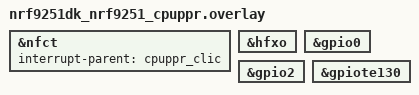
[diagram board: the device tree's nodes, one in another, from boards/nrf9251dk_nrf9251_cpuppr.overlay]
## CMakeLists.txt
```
#
# Copyright (c) 2018 Nordic Semiconductor
#
# SPDX-License-Identifier: LicenseRef-Nordic-5-Clause
#

cmake_minimum_required(VERSION 3.20.0)

find_package(Zephyr REQUIRED HINTS $ENV{ZEPHYR_BASE})
project(NONE)

FILE(GLOB app_sources src/*.c)
# NORDIC SDK APP START
target_sources(app  PRIVATE ${app_sources})
# NORDIC SDK APP END
```

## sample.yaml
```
sample:
  name: NFC text record sample
tests:
  sample.nfc.record_text:
    sysbuild: true
    build_only: true
    integration_platforms:
      - nrf52840dk/nrf52840
      - nrf5340dk/nrf5340/cpuapp
      - nrf5340dk/nrf5340/cpuapp/ns
      - nrf54h20dk/nrf54h20/cpuapp
      - nrf54l15dk/nrf54l05/cpuapp
      - nrf54l15dk/nrf54l10/cpuapp
      - nrf54l15dk/nrf54l15/cpuapp
      - nrf54l15dk/nrf54l15/cpuapp/ns
      - nrf54lm20dk/nrf54lm20a/cpuapp
      - nrf7120dk/nrf7120/cpuapp
    platform_allow:
      - nrf52840dk/nrf52840
      - nrf52dk/nrf52832
      - nrf5340dk/nrf5340/cpuapp
      - nrf5340dk/nrf5340/cpuapp/ns
      - nrf54h20dk/nrf54h20/cpuapp
      - nrf54l15dk/nrf54l05/cpuapp
      - nrf54l15dk/nrf54l10/cpuapp
      - nrf54l15dk/nrf54l15/cpuapp
      - nrf54l15dk/nrf54l15/cpuapp/ns
      - nrf54lm20dk/nrf54lm20a/cpuapp
      - nrf7120dk/nrf7120/cpuapp
    tags:
      - ci_build
      - sysbuild
      - ci_samples_nfc
```

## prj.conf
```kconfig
#
# Copyright (c) 2019 Nordic Semiconductor ASA
#
# SPDX-License-Identifier: LicenseRef-Nordic-5-Clause
#
CONFIG_NCS_SAMPLES_DEFAULTS=y

CONFIG_REBOOT=y
CONFIG_DK_LIBRARY=y

CONFIG_NFC_T2T_NRFXLIB=y

CONFIG_NFC_NDEF=y
CONFIG_NFC_NDEF_MSG=y
CONFIG_NFC_NDEF_RECORD=y
CONFIG_NFC_NDEF_TEXT_RECORD=y
```

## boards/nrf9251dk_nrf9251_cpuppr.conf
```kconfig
#
# Copyright (c) 2026 Nordic Semiconductor ASA
#
# SPDX-License-Identifier: LicenseRef-Nordic-5-Clause
#

# Disable NFC low latency IRQ
CONFIG_NFC_LOW_LATENCY_IRQ=n

CONFIG_DK_LIBRARY=n
```

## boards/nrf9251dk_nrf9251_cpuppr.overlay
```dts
/*
 * Copyright (c) 2026 Nordic Semiconductor ASA
 *
 * SPDX-License-Identifier: LicenseRef-Nordic-5-Clause
 */

&nfct {
	status = "okay";
	interrupt-parent = <&cpuppr_clic>;
};

&hfxo {
	status = "okay";
};

&gpio0 {
	status = "okay";
};

&gpio2 {
	status = "okay";
};

&gpiote130 {
	status = "okay";
};
```

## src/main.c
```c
/*
 * Copyright (c) 2018 Nordic Semiconductor ASA
 *
 * SPDX-License-Identifier: LicenseRef-Nordic-5-Clause
 */

#include <zephyr/kernel.h>
#if defined(CONFIG_REBOOT)
#include <zephyr/sys/reboot.h>
#endif /* CONFIG_REBOOT */

#include <nfc_t2t_lib.h>
#include <nfc/ndef/msg.h>
#include <nfc/ndef/text_rec.h>

#if defined(CONFIG_DK_LIBRARY)
#include <dk_buttons_and_leds.h>

#define NFC_FIELD_LED		DK_LED1
#endif /* CONFIG_DK_LIBRARY */

#define MAX_REC_COUNT		3
#define NDEF_MSG_BUF_SIZE	128

/* Text message in English with its language code. */
static const uint8_t en_payload[] = {
	'H', 'e', 'l', 'l', 'o', ' ', 'W', 'o', 'r', 'l', 'd', '!'
};
static const uint8_t en_code[] = {'e', 'n'};

/* Text message in Norwegian with its language code. */
static const uint8_t no_payload[] = {
	'H', 'a', 'l', 'l', 'o', ' ', 'V', 'e', 'r', 'd', 'e', 'n', '!'
};
static const uint8_t no_code[] = {'N', 'O'};

/* Text message in Polish with its language code. */
static const uint8_t pl_payload[] = {
	'W', 'i', 't', 'a', 'j', ' ', 0xc5, 0x9a, 'w', 'i', 'e', 'c', 'i',
	'e', '!'
};
static const uint8_t pl_code[] = {'P', 'L'};

/* Buffer used to hold an NFC NDEF message. */
static uint8_t ndef_msg_buf[NDEF_MSG_BUF_SIZE];

static void nfc_callback(void *context,
			 nfc_t2t_event_t event,
			 const uint8_t *data,
			 size_t data_length)
{
	ARG_UNUSED(context);
	ARG_UNUSED(data);
	ARG_UNUSED(data_length);

	switch (event) {
	case NFC_T2T_EVENT_FIELD_ON:
#if defined(CONFIG_DK_LIBRARY)
		dk_set_led_on(NFC_FIELD_LED);
#endif /* CONFIG_DK_LIBRARY */
		break;
	case NFC_T2T_EVENT_FIELD_OFF:
#if defined(CONFIG_DK_LIBRARY)
		dk_set_led_off(NFC_FIELD_LED);
#endif /* CONFIG_DK_LIBRARY */
		break;
	default:
		break;
	}
}

/**
 * @brief Function for encoding the NDEF text message.
 */
static int welcome_msg_encode(uint8_t *buffer, uint32_t *len)
{
	int err;

	/* Create NFC NDEF text record description in English */
	NFC_NDEF_TEXT_RECORD_DESC_DEF(nfc_en_text_rec,
				      UTF_8,
				      en_code,
				      sizeof(en_code),
				      en_payload,
				      sizeof(en_payload));

	/* Create NFC NDEF text record description in Norwegian */
	NFC_NDEF_TEXT_RECORD_DESC_DEF(nfc_no_text_rec,
				      UTF_8,
				      no_code,
				      sizeof(no_code),
				      no_payload,
				      sizeof(no_payload));

	/* Create NFC NDEF text record description in Polish */
	NFC_NDEF_TEXT_RECORD_DESC_DEF(nfc_pl_text_rec,
				      UTF_8,
				      pl_code,
				      sizeof(pl_code),
				      pl_payload,
				      sizeof(pl_payload));

	/* Create NFC NDEF message description, capacity - MAX_REC_COUNT
	 * records
	 */
	NFC_NDEF_MSG_DEF(nfc_text_msg, MAX_REC_COUNT);

	/* Add text records to NDEF text message */
	err = nfc_ndef_msg_record_add(&NFC_NDEF_MSG(nfc_text_msg),
				   &NFC_NDEF_TEXT_RECORD_DESC(nfc_en_text_rec));
	if (err < 0) {
		printk("Cannot add first record!\n");
		return err;
	}
	err = nfc_ndef_msg_record_add(&NFC_NDEF_MSG(nfc_text_msg),
				   &NFC_NDEF_TEXT_RECORD_DESC(nfc_no_text_rec));
	if (err < 0) {
		printk("Cannot add second record!\n");
		return err;
	}
	err = nfc_ndef_msg_record_add(&NFC_NDEF_MSG(nfc_text_msg),
				   &NFC_NDEF_TEXT_RECORD_DESC(nfc_pl_text_rec));
	if (err < 0) {
		printk("Cannot add third record!\n");
		return err;
	}

	err = nfc_ndef_msg_encode(&NFC_NDEF_MSG(nfc_text_msg),
				      buffer,
				      len);
	if (err < 0) {
		printk("Cannot encode message!\n");
	}

	return err;
}


int main(void)
{
	uint32_t len = sizeof(ndef_msg_buf);

	printk("Starting NFC Text Record sample\n");

#if defined(CONFIG_DK_LIBRARY)
	/* Configure LED-pins as outputs */
	if (dk_leds_init() < 0) {
		printk("Cannot init LEDs!\n");
		goto fail;
	}
#endif /* CONFIG_DK_LIBRARY */

	/* Set up NFC */
	if (nfc_t2t_setup(nfc_callback, NULL) < 0) {
		printk("Cannot setup NFC T2T library!\n");
		goto fail;
	}


	/* Encode welcome message */
	if (welcome_msg_encode(ndef_msg_buf, &len) < 0) {
		printk("Cannot encode message!\n");
		goto fail;
	}


	/* Set created message as the NFC payload */
	if (nfc_t2t_payload_set(ndef_msg_buf, len) < 0) {
		printk("Cannot set payload!\n");
		goto fail;
	}


	/* Start sensing NFC field */
	if (nfc_t2t_emulation_start() < 0) {
		printk("Cannot start emulation!\n");
		goto fail;
	}
	printk("NFC configuration done\n");

	return 0;

fail:
#if defined(CONFIG_REBOOT)
	sys_reboot(SYS_REBOOT_COLD);
#endif /* CONFIG_REBOOT */

	return -EIO;
}
```
